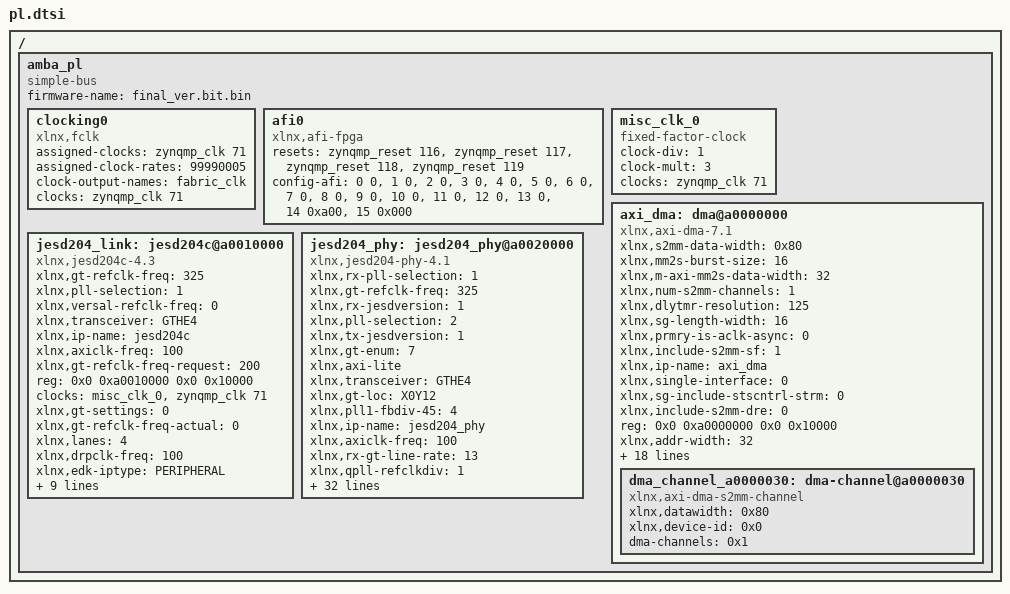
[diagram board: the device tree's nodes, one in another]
/ {
	amba_pl: amba_pl {
		ranges;
		compatible = "simple-bus";
		#address-cells = <2>;
		#size-cells = <2>;
		firmware-name = "final_ver.bit.bin";
		clocking0: clocking0 {
			compatible = "xlnx,fclk";
			status = "okay";
			assigned-clocks = <&zynqmp_clk 71>;
			assigned-clock-rates = <99990005>;
			#clock-cells = <0>;
			clock-output-names = "fabric_clk";
			clocks = <&zynqmp_clk 71>;
		};
		afi0: afi0 {
			status = "okay";
			compatible = "xlnx,afi-fpga";
			resets = <&zynqmp_reset 116>, <&zynqmp_reset 117>, <&zynqmp_reset 118>, <&zynqmp_reset 119>;
			config-afi = < 0 0>, <1 0>, <2 0>, <3 0>, <4 0>, <5 0>, <6 0>, <7 0>, <8 0>, <9 0>, <10 0>, <11 0>, <12 0>, <13 0>, <14 0xa00>, <15 0x000>;
		};
		misc_clk_0: misc_clk_0 {
			clock-div = <1>;
			compatible = "fixed-factor-clock";
			clock-mult = <3>;
			clocks = <&zynqmp_clk 71>;
			#clock-cells = <0>;
		};
		axi_dma: dma@a0000000 {
			compatible = "xlnx,axi-dma-7.1" , "xlnx,axi-dma-1.00.a";
			xlnx,s2mm-data-width = <0x80>;
			xlnx,mm2s-burst-size = <16>;
			xlnx,m-axi-mm2s-data-width = <32>;
			xlnx,num-s2mm-channels = <1>;
			xlnx,dlytmr-resolution = <125>;
			xlnx,sg-length-width = <16>;
			xlnx,prmry-is-aclk-async = <0>;
			xlnx,include-s2mm-sf = <1>;
			#dma-cells = <1>;
			xlnx,ip-name = "axi_dma";
			xlnx,single-interface = <0>;
			xlnx,sg-include-stscntrl-strm = <0>;
			xlnx,include-s2mm-dre = <0>;
			reg = <0x0 0xa0000000 0x0 0x10000>;
			xlnx,addr-width = <32>;
			xlnx,include-s2mm = <1>;
			clocks = <&zynqmp_clk 71>, <&zynqmp_clk 71>;
			xlnx,s-axis-s2mm-tdata-width = <128>;
			xlnx,micro-dma = <0>;
			xlnx,increase-throughput = <0>;
			xlnx,mm2s-data-width = <0x20>;
			xlnx,addrwidth = <0x20>;
			xlnx,sg-use-stsapp-length = <0>;
			xlnx,m-axis-mm2s-tdata-width = <32>;
			xlnx,edk-iptype = "PERIPHERAL";
			xlnx,s2mm-burst-size = <16>;
			xlnx,m-axi-s2mm-data-width = <128>;
			xlnx,num-mm2s-channels = <1>;
			xlnx,enable-multi-channel = <0>;
			status = "okay";
			xlnx,include-mm2s-sf = <1>;
			clock-names = "m_axi_s2mm_aclk" , "s_axi_lite_aclk";
			xlnx,include-mm2s = <0>;
			xlnx,include-mm2s-dre = <0>;
			xlnx,name = "axi_dma";
			dma_channel_a0000030: dma-channel@a0000030 {
				xlnx,datawidth = <0x80>;
				xlnx,device-id = <0x0>;
				compatible = "xlnx,axi-dma-s2mm-channel";
				dma-channels = <0x1>;
			};
		};
		jesd204_link: jesd204c@a0010000 {
			compatible = "xlnx,jesd204c-4.3";
			xlnx,gt-refclk-freq = <325>;
			xlnx,pll-selection = <1>;
			xlnx,versal-refclk-freq = <0>;
			xlnx,transceiver = "GTHE4";
			xlnx,ip-name = "jesd204c";
			xlnx,axiclk-freq = <100>;
			xlnx,gt-refclk-freq-request = <200>;
			reg = <0x0 0xa0010000 0x0 0x10000>;
			clocks = <&misc_clk_0>, <&zynqmp_clk 71>;
			xlnx,gt-settings = <0>;
			xlnx,gt-refclk-freq-actual = <0>;
			xlnx,lanes = <4>;
			xlnx,drpclk-freq = <100>;
			xlnx,edk-iptype = "PERIPHERAL";
			xlnx,speedgrade = <0xfffffffe>;
			xlnx,sub-core-name = "NO_SUBCORE";
			xlnx,node-is-transmit = <0>;
			status = "okay";
			clock-names = "rx_core_clk" , "s_axi_aclk";
			xlnx,encoding = <0>;
			xlnx,versal-refclk-requested = <200>;
			xlnx,gt-wizard-type = <0>;
			xlnx,name = "jesd204_link";
			xlnx,component-name = "system_jesd204c_0_0";
			xlnx,gt-line-rate = <13>;
		};
		jesd204_phy: jesd204_phy@a0020000 {
			xlnx,rx-pll-selection = <1>;
			xlnx,gt-refclk-freq = <325>;
			compatible = "xlnx,jesd204-phy-4.1";
			xlnx,rx-jesdversion = <1>;
			xlnx,pll-selection = <2>;
			xlnx,tx-jesdversion = <1>;
			xlnx,gt-enum = <7>;
			xlnx,axi-lite;
			xlnx,transceiver = "GTHE4";
			xlnx,gt-loc = "X0Y12";
			xlnx,pll1-fbdiv-45 = <4>;
			xlnx,ip-name = "jesd204_phy";
			xlnx,axiclk-freq = <100>;
			xlnx,rx-gt-line-rate = <13>;
			xlnx,qpll-refclkdiv = <1>;
			xlnx,pll0-fbdiv = <1>;
			xlnx,ins-loss = <12>;
			reg = <0x0 0xa0020000 0x0 0x10000>;
			xlnx,channel-pos = <0>;
			clocks = <&misc_clk_0>, <&zynqmp_clk 71>, <&misc_clk_0>, <&misc_clk_0>, <&misc_clk_0>, <&zynqmp_clk 71>, <&misc_clk_0>;
			xlnx,gt-location = "X0Y12";
			xlnx,rx-gt-refclk-freq = <325>;
			xlnx,pll1-fbdiv = <1>;
			xlnx,min-line-rate = <13>;
			xlnx,lanes = <4>;
			xlnx,drpclk-freq = <100>;
			xlnx,edk-iptype = "PERIPHERAL";
			xlnx,speedgrade = <0xfffffffe>;
			xlnx,max-line-rate = <13>;
			xlnx,supportlevel = <1>;
			xlnx,rx-use-64b = <0>;
			xlnx,rx-masterchan = <1>;
			xlnx,config-type = <0>;
			xlnx,sub-core-name = "system_jesd204_phy_0_0_gt";
			xlnx,quads = <1>;
			xlnx,pll0-fbdiv-45 = <4>;
			status = "okay";
			clock-names = "cpll_refclk" , "drpclk" , "qpll0_refclk" , "qpll1_refclk" , "rx_core_clk" , "s_axi_aclk" , "tx_core_clk";
			xlnx,tx-use-64b = <0>;
			xlnx,tx-masterchan = <1>;
			xlnx,pll0-refclkdiv = <1>;
			xlnx,pll1-refclkdiv = <1>;
			xlnx,equalization-mode = <0>;
			xlnx,qpll-fbdiv = <40>;
			xlnx,gt-line-rate = <13>;
			xlnx,name = "jesd204_phy";
			xlnx,component-name = "system_jesd204_phy_0_0";
		};
	};
};
